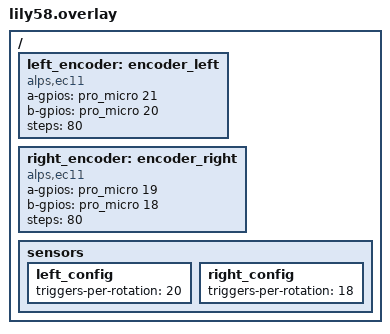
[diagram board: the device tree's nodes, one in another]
/ {
    left_encoder: encoder_left {
        compatible = "alps,ec11";
        a-gpios = <&pro_micro 21 (GPIO_ACTIVE_HIGH | GPIO_PULL_UP)>;
        b-gpios = <&pro_micro 20 (GPIO_ACTIVE_HIGH | GPIO_PULL_UP)>;
        steps = <80>;
    };

    right_encoder: encoder_right {
        compatible = "alps,ec11";
        a-gpios = <&pro_micro 19 (GPIO_ACTIVE_HIGH | GPIO_PULL_UP)>;
        b-gpios = <&pro_micro 18 (GPIO_ACTIVE_HIGH | GPIO_PULL_UP)>;
        steps = <80>;
    };

    sensors: sensors {
        left_config {
            triggers-per-rotation = <20>;
        };

        right_config {
            triggers-per-rotation = <18>;
        };
    };
};
